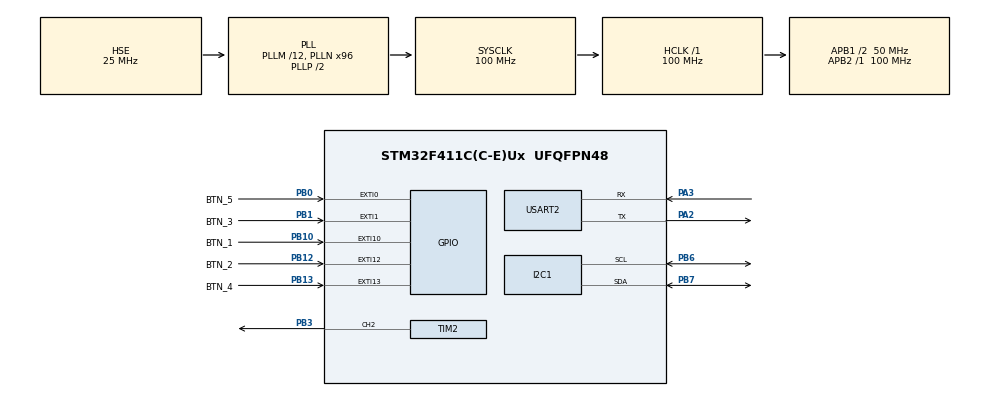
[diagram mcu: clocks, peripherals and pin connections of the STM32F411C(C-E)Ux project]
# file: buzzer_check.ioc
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FREERTOS.Tasks01=defaultTask,0,128,StartDefaultTask,Default,NULL,Dynamic,NULL,NULL
Mcu.Family=STM32F4
Mcu.Name=STM32F411C(C-E)Ux
Mcu.Package=UFQFPN48
NVIC.PriorityGroup=NVIC_PRIORITYGROUP_4
PA2.Mode=Asynchronous
PA2.Signal=USART2_TX
PA3.Mode=Asynchronous
PA3.Signal=USART2_RX
PB0.GPIO_Label=BTN_5
PB0.GPIO_ModeDefaultEXTI=GPIO_MODE_IT_RISING_FALLING
PB0.GPIO_PuPd=GPIO_PULLUP
PB0.Signal=GPXTI0
PB1.GPIO_Label=BTN_3
PB1.GPIO_ModeDefaultEXTI=GPIO_MODE_IT_RISING_FALLING
PB1.GPIO_PuPd=GPIO_PULLUP
PB1.Signal=GPXTI1
PB10.GPIO_Label=BTN_1
PB10.GPIO_ModeDefaultEXTI=GPIO_MODE_IT_RISING_FALLING
PB10.GPIO_PuPd=GPIO_PULLUP
PB10.Signal=GPXTI10
PB12.GPIO_Label=BTN_2
PB12.GPIO_ModeDefaultEXTI=GPIO_MODE_IT_RISING_FALLING
PB12.GPIO_PuPd=GPIO_PULLUP
PB12.Signal=GPXTI12
PB13.GPIO_Label=BTN_4
PB13.GPIO_ModeDefaultEXTI=GPIO_MODE_IT_FALLING
PB13.GPIO_PuPd=GPIO_PULLUP
PB13.Signal=GPXTI13
PB3.Signal=S_TIM2_CH2
PB6.Mode=I2C
PB6.Signal=I2C1_SCL
PB7.Mode=I2C
PB7.Signal=I2C1_SDA
PH0\ -\ OSC_IN.Mode=HSE-External-Oscillator
PH0\ -\ OSC_IN.Signal=RCC_OSC_IN
PH1\ -\ OSC_OUT.Mode=HSE-External-Oscillator
PH1\ -\ OSC_OUT.Signal=RCC_OSC_OUT
ProjectManager.HeapSize=0x200
ProjectManager.StackSize=0x400
ProjectManager.TargetToolchain=STM32CubeIDE
RCC.48MHZClocksFreq_Value=50000000
RCC.AHBFreq_Value=100000000
RCC.APB1CLKDivider=RCC_HCLK_DIV2
RCC.APB1Freq_Value=50000000
RCC.APB1TimFreq_Value=100000000
RCC.APB2Freq_Value=100000000
RCC.APB2TimFreq_Value=100000000
RCC.CortexFreq_Value=100000000
RCC.HCLKFreq_Value=100000000
RCC.HSE_VALUE=25000000
RCC.HSI_VALUE=16000000
RCC.LSE_VALUE=32768
RCC.PLLM=12
RCC.PLLN=96
RCC.PLLSourceVirtual=RCC_PLLSOURCE_HSE
RCC.SYSCLKFreq_VALUE=100000000
RCC.SYSCLKSource=RCC_SYSCLKSOURCE_PLLCLK
RCC.VCOOutputFreq_Value=200000000
SH.S_TIM2_CH2.0=TIM2_CH2,PWM Generation2 CH2
TIM2.Channel-PWM\ Generation2\ CH2=TIM_CHANNEL_2
TIM2.Period=5000
TIM2.Prescaler=2-1
TIM2.Pulse-PWM\ Generation2\ CH2=50
USART2.VirtualMode=VM_ASYNC
VP_FREERTOS_VS_CMSIS_V1.Mode=CMSIS_V1
VP_TIM2_VS_ClockSourceINT.Mode=Internal
board=custom

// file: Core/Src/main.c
/* USER CODE BEGIN Header */
/**
  ******************************************************************************
  * @file           : main.c
  * @brief          : Main program body
  ******************************************************************************
  * @attention
  *
  * Copyright (c) 2025 STMicroelectronics.
  * All rights reserved.
  *
  * This software is licensed under terms that can be found in the LICENSE file
  * in the root directory of this software component.
  * If no LICENSE file comes with this software, it is provided AS-IS.
  *
  ******************************************************************************
  */
/* USER CODE END Header */
#include "main.h"
#include "cmsis_os.h"

/* USER CODE BEGIN Includes */
#include "ssd1306.h"
#include "ssd1306_fonts.h"
#include <stdio.h>
#include <string.h>
#include "buzzer.h"
#include "pong.h"
#include "menu.h"
#include "comm.h"
#include "todo.h"
#include "image_viewer.h"

/* USER CODE END Includes */

I2C_HandleTypeDef hi2c1;

TIM_HandleTypeDef htim2;

UART_HandleTypeDef huart2;

osThreadId defaultTaskHandle;

void SystemClock_Config(void);
static void MX_GPIO_Init(void);
static void MX_TIM2_Init(void);
static void MX_I2C1_Init(void);
static void MX_USART2_UART_Init(void);
void StartDefaultTask(void const * argument);

int main(void)
{

  /* MCU Configuration--------------------------------------------------------*/

  /* Reset of all peripherals, Initializes the Flash interface and the Systick. */
  HAL_Init();

  /* Configure the system clock */
  SystemClock_Config();

  /* Initialize all configured peripherals */
  MX_GPIO_Init();
  MX_TIM2_Init();
  MX_I2C1_Init();
  MX_USART2_UART_Init();
  /* USER CODE BEGIN 2 */
//  TIM2->CCR1=2500;
//  HAL_TIM_PWM_Start(&htim2, TIM_CHANNEL_2);
//  HAL_Delay(1000);
//  HAL_TIM_PWM_Stop(&htim2, TIM_CHANNEL_2);
//  buzzer_init();
  ssd1306_Init();

  comm_init();
  /* USER CODE END 2 */

  /* Create the thread(s) */
  /* definition and creation of defaultTask */
  osThreadDef(defaultTask, StartDefaultTask, osPriorityNormal, 0, 128);
  defaultTaskHandle = osThreadCreate(osThread(defaultTask), NULL);

  /* Start scheduler */
  osKernelStart();

  /* We should never get here as control is now taken by the scheduler */

  /* Infinite loop */
  while (1)
  {

  }
}

void SystemClock_Config(void)
{
  RCC_OscInitTypeDef RCC_OscInitStruct = {0};
  RCC_ClkInitTypeDef RCC_ClkInitStruct = {0};

  /** Configure the main internal regulator output voltage
  */
  __HAL_RCC_PWR_CLK_ENABLE();
  __HAL_PWR_VOLTAGESCALING_CONFIG(PWR_REGULATOR_VOLTAGE_SCALE1);

  /** Initializes the RCC Oscillators according to the specified parameters
  * in the RCC_OscInitTypeDef structure.
  */
  RCC_OscInitStruct.OscillatorType = RCC_OSCILLATORTYPE_HSE;
  RCC_OscInitStruct.HSEState = RCC_HSE_ON;
  RCC_OscInitStruct.PLL.PLLState = RCC_PLL_ON;
  RCC_OscInitStruct.PLL.PLLSource = RCC_PLLSOURCE_HSE;
  RCC_OscInitStruct.PLL.PLLM = 12;
  RCC_OscInitStruct.PLL.PLLN = 96;
  RCC_OscInitStruct.PLL.PLLP = RCC_PLLP_DIV2;
  RCC_OscInitStruct.PLL.PLLQ = 4;
  if (HAL_RCC_OscConfig(&RCC_OscInitStruct) != HAL_OK)
  {
    Error_Handler();
  }

  /** Initializes the CPU, AHB and APB buses clocks
  */
  RCC_ClkInitStruct.ClockType = RCC_CLOCKTYPE_HCLK|RCC_CLOCKTYPE_SYSCLK
                              |RCC_CLOCKTYPE_PCLK1|RCC_CLOCKTYPE_PCLK2;
  RCC_ClkInitStruct.SYSCLKSource = RCC_SYSCLKSOURCE_PLLCLK;
  RCC_ClkInitStruct.AHBCLKDivider = RCC_SYSCLK_DIV1;
  RCC_ClkInitStruct.APB1CLKDivider = RCC_HCLK_DIV2;
  RCC_ClkInitStruct.APB2CLKDivider = RCC_HCLK_DIV1;

  if (HAL_RCC_ClockConfig(&RCC_ClkInitStruct, FLASH_LATENCY_3) != HAL_OK)
  {
    Error_Handler();
  }
}

static void MX_I2C1_Init(void)
{

  hi2c1.Instance = I2C1;
  hi2c1.Init.ClockSpeed = 100000;
  hi2c1.Init.DutyCycle = I2C_DUTYCYCLE_2;
  hi2c1.Init.OwnAddress1 = 0;
  hi2c1.Init.AddressingMode = I2C_ADDRESSINGMODE_7BIT;
  hi2c1.Init.DualAddressMode = I2C_DUALADDRESS_DISABLE;
  hi2c1.Init.OwnAddress2 = 0;
  hi2c1.Init.GeneralCallMode = I2C_GENERALCALL_DISABLE;
  hi2c1.Init.NoStretchMode = I2C_NOSTRETCH_DISABLE;
  if (HAL_I2C_Init(&hi2c1) != HAL_OK)
  {
    Error_Handler();
  }

}

static void MX_TIM2_Init(void)
{

  TIM_ClockConfigTypeDef sClockSourceConfig = {0};
  TIM_MasterConfigTypeDef sMasterConfig = {0};
  TIM_OC_InitTypeDef sConfigOC = {0};

  htim2.Instance = TIM2;
  htim2.Init.Prescaler = 2-1;
  htim2.Init.CounterMode = TIM_COUNTERMODE_UP;
  htim2.Init.Period = 5000;
  htim2.Init.ClockDivision = TIM_CLOCKDIVISION_DIV1;
  htim2.Init.AutoReloadPreload = TIM_AUTORELOAD_PRELOAD_DISABLE;
  if (HAL_TIM_Base_Init(&htim2) != HAL_OK)
  {
    Error_Handler();
  }
  sClockSourceConfig.ClockSource = TIM_CLOCKSOURCE_INTERNAL;
  if (HAL_TIM_ConfigClockSource(&htim2, &sClockSourceConfig) != HAL_OK)
  {
    Error_Handler();
  }
  if (HAL_TIM_PWM_Init(&htim2) != HAL_OK)
  {
    Error_Handler();
  }
  sMasterConfig.MasterOutputTrigger = TIM_TRGO_RESET;
  sMasterConfig.MasterSlaveMode = TIM_MASTERSLAVEMODE_DISABLE;
  if (HAL_TIMEx_MasterConfigSynchronization(&htim2, &sMasterConfig) != HAL_OK)
  {
    Error_Handler();
  }
  sConfigOC.OCMode = TIM_OCMODE_PWM1;
  sConfigOC.Pulse = 50;
  sConfigOC.OCPolarity = TIM_OCPOLARITY_HIGH;
  sConfigOC.OCFastMode = TIM_OCFAST_DISABLE;
  if (HAL_TIM_PWM_ConfigChannel(&htim2, &sConfigOC, TIM_CHANNEL_2) != HAL_OK)
  {
    Error_Handler();
  }
  HAL_TIM_MspPostInit(&htim2);

}

static void MX_USART2_UART_Init(void)
{

  huart2.Instance = USART2;
  huart2.Init.BaudRate = 115200;
  huart2.Init.WordLength = UART_WORDLENGTH_8B;
  huart2.Init.StopBits = UART_STOPBITS_1;
  huart2.Init.Parity = UART_PARITY_NONE;
  huart2.Init.Mode = UART_MODE_TX_RX;
  huart2.Init.HwFlowCtl = UART_HWCONTROL_NONE;
  huart2.Init.OverSampling = UART_OVERSAMPLING_16;
  if (HAL_UART_Init(&huart2) != HAL_OK)
  {
    Error_Handler();
  }

}

static void MX_GPIO_Init(void)
{
  GPIO_InitTypeDef GPIO_InitStruct = {0};

  /* GPIO Ports Clock Enable */
  __HAL_RCC_GPIOH_CLK_ENABLE();
  __HAL_RCC_GPIOA_CLK_ENABLE();
  __HAL_RCC_GPIOB_CLK_ENABLE();

  /*Configure GPIO pins : BTN_5_Pin BTN_3_Pin BTN_1_Pin BTN_2_Pin */
  GPIO_InitStruct.Pin = BTN_5_Pin|BTN_3_Pin|BTN_1_Pin|BTN_2_Pin;
  GPIO_InitStruct.Mode = GPIO_MODE_IT_RISING_FALLING;
  GPIO_InitStruct.Pull = GPIO_PULLUP;
  HAL_GPIO_Init(GPIOB, &GPIO_InitStruct);

  /*Configure GPIO pin : BTN_4_Pin */
  GPIO_InitStruct.Pin = BTN_4_Pin;
  GPIO_InitStruct.Mode = GPIO_MODE_IT_FALLING;
  GPIO_InitStruct.Pull = GPIO_PULLUP;
  HAL_GPIO_Init(BTN_4_GPIO_Port, &GPIO_InitStruct);

}

//void StartDefaultTask(void const * argument)
//{
//  /* USER CODE BEGIN 5 */
//  /* Infinite loop */
//  menu_init();
//  int cnt = 1000;
//  for(;;)
//  {
//    AppID app = menu_run();
//    osDelay(50);
//    if(app == APP_SNAKE){
//
//    }
//    else if(app == APP_PONG){
//      int score = pong_run();
//    }
//    else{
//      osDelay(10);
//    }
////	  buzzer_beep();
//////    cnt-=50;
////    if(cnt >= 100){
////    	cnt-=50;
////    	osDelay(100);
////    }else{
////    	cnt = 1;
////    }
////    osDelay(cnt);
//    osDelay(1);
//  }
//  /* USER CODE END 5 */
//}

void StartDefaultTask(void const * argument)
{
  menu_init();

  for(;;)
  {
    AppID app = menu_run();
    osDelay(50);

    if (app == APP_SNAKE) {
        // snake_run();
    }
    else if (app == APP_PONG) {
        int score = pong_run();
        (void)score;
    }
    else if (app == APP_TODO) {
        todo_run();
    }
    else if (app == APP_IMAGE) {
        image_viewer_run();
    }
    else {
        osDelay(10);
    }

    osDelay(1);
  }
}

//void StartDefaultTask(void const * argument) {
//	ssd1306_Init();
//	while (1) {
//		ssd1306_Fill(Black);
//		ssd1306_SetCursor(10, 20);
//		ssd1306_WriteString("READY! Press UP", Font_7x10, White);
//		ssd1306_UpdateScreen();
//		if (HAL_GPIO_ReadPin(GPIOB, BTN_1_Pin) == 0)
//		{ HAL_Delay(200);
//		// ssd1306_SetCursor(10, 40);
//		// ssd1306_WriteString("khotya kardiya press", Font_7x10, White);
//		// ssd1306_UpdateScreen();
////		buzzer_laser(); // BLOCKS until exit
//		buzzer_fail();
//		osDelay(20); }
//		}
//}

void Error_Handler(void)
{
  __disable_irq();
  while (1)
  {
  }
}
